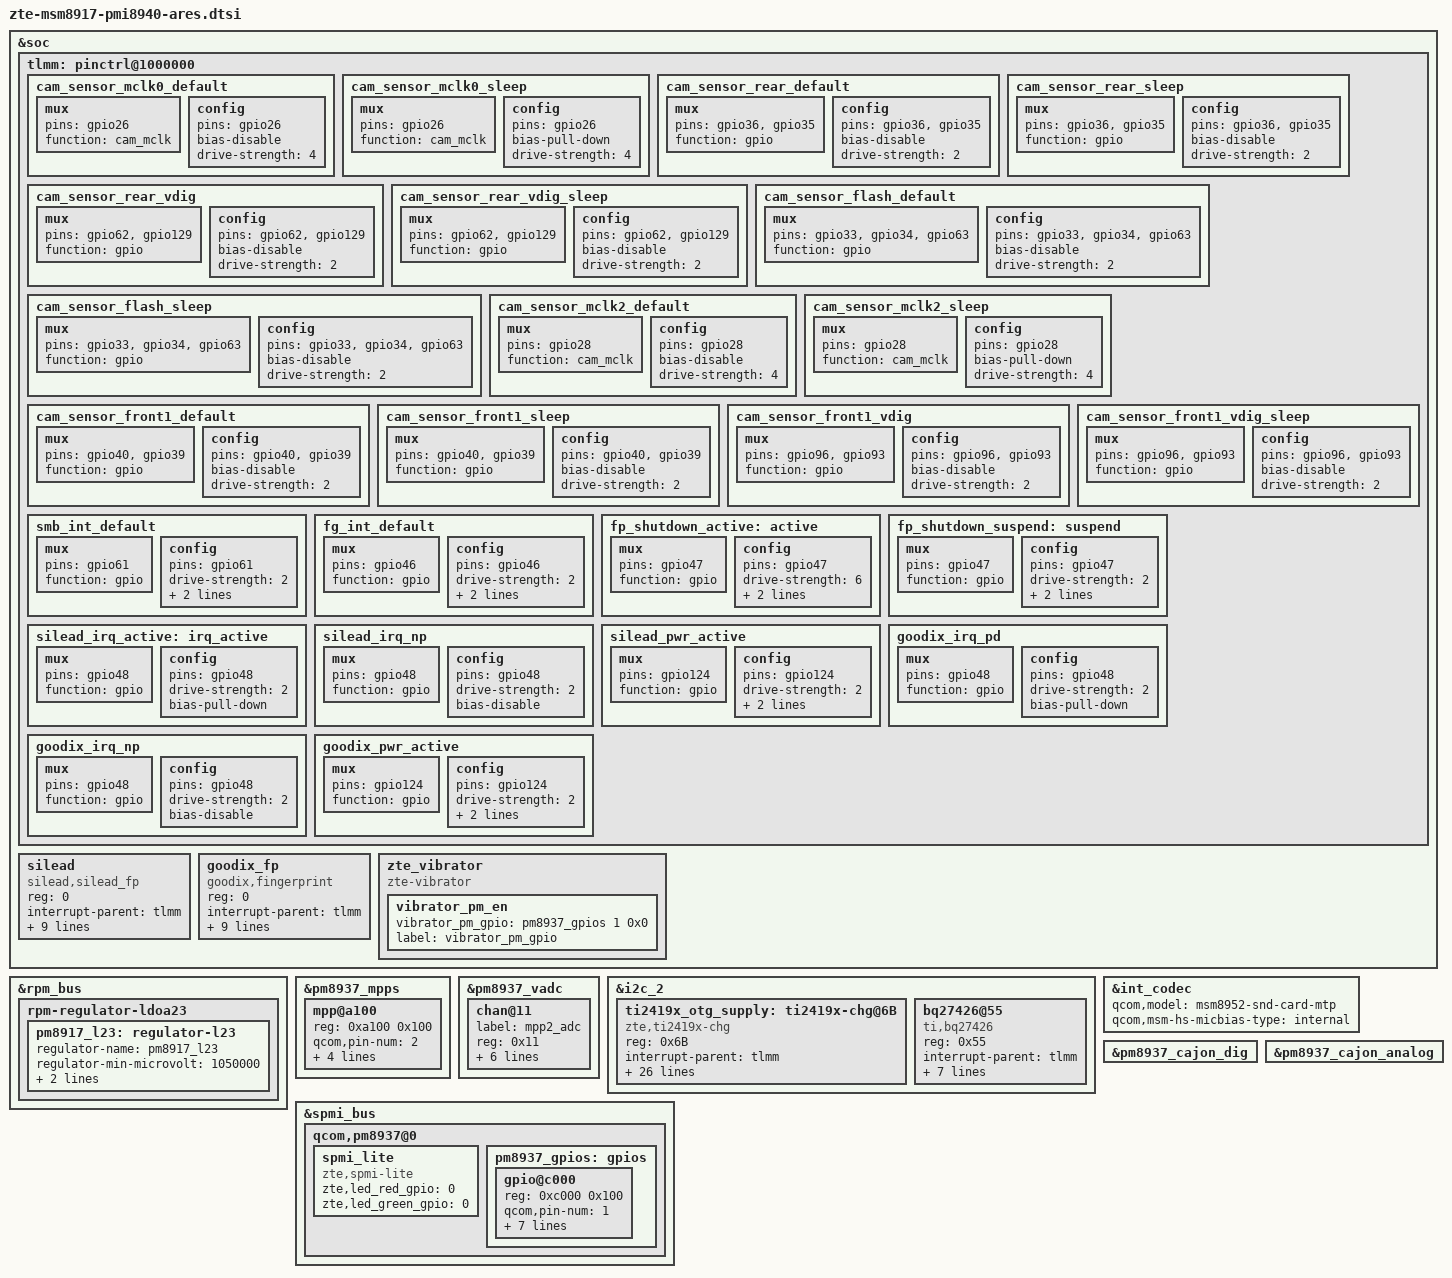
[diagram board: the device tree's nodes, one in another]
/*
 * Copyright (c) 2016, The Linux Foundation. All rights reserved.
 *
 * This program is free software; you can redistribute it and/or modify
 * it under the terms of the GNU General Public License version 2 and
 * only version 2 as published by the Free Software Foundation.
 *
 * This program is distributed in the hope that it will be useful,
 * but WITHOUT ANY WARRANTY; without even the implied warranty of
 * MERCHANTABILITY or FITNESS FOR A PARTICULAR PURPOSE.  See the
 * GNU General Public License for more details.
 */

/*
* device tree for zte ares board
*/

/*ZTE yuxin add for zte Z5151CA ares prj camera gpios 2017.12.16 begin*/
&soc {
	tlmm: pinctrl@1000000 {
	/*sensors */
		cam_sensor_mclk0_default: cam_sensor_mclk0_default {
			/* MCLK0 */
				mux {
				/* CLK, DATA */
				pins = "gpio26";
				function = "cam_mclk";
			};

			config {
				pins = "gpio26";
				bias-disable; /* No PULL */
				drive-strength = <4>; /* 2 MA */
			};
		};

		cam_sensor_mclk0_sleep: cam_sensor_mclk0_sleep {
			/* MCLK0 */
			mux {
				/* CLK, DATA */
				pins = "gpio26";
				function = "cam_mclk";
			};

			config {
				pins = "gpio26";
				bias-pull-down; /* PULL DOWN */
				drive-strength = <4>; /* 2 MA */
			};
		};

		cam_sensor_rear_default: cam_sensor_rear_default {
			/* RESET, STANDBY */
			mux {
				pins = "gpio36", "gpio35";
				function = "gpio";
			};

			config {
				pins = "gpio36","gpio35";
				bias-disable; /* No PULL */
				drive-strength = <2>; /* 2 MA */
			};
		};

		cam_sensor_rear_sleep: cam_sensor_rear_sleep {
			/* RESET, STANDBY */
			mux {
				pins = "gpio36","gpio35";
				function = "gpio";
			};

			config {
				pins = "gpio36","gpio35";
				bias-disable; /* No PULL */
				drive-strength = <2>; /* 2 MA */
			};
		};

		cam_sensor_rear_vdig: cam_sensor_rear_vdig {
			/* VDIG */
			mux {
				pins = "gpio62","gpio129";
				function = "gpio";
			};

			config {
				pins = "gpio62","gpio129";
				bias-disable; /* No PULL */
				drive-strength = <2>; /* 2 MA */
			};
		};

		cam_sensor_rear_vdig_sleep: cam_sensor_rear_vdig_sleep {
			/* VDIG */
			mux {
				pins = "gpio62","gpio129";
				function = "gpio";
			};

			config {
				pins = "gpio62","gpio129";
				bias-disable; /* No PULL */
				drive-strength = <2>; /* 2 MA */
			};
		};
		/*yuxin add for Z5151V flash 20180123 ++*/
		cam_sensor_flash_default: cam_sensor_flash_default {
			/* VDIG */
			mux {
				pins = "gpio33", "gpio34", "gpio63";
				function = "gpio";
			};

			config {
				pins = "gpio33", "gpio34", "gpio63";
				bias-disable; /* No PULL */
				drive-strength = <2>; /* 2 MA */
			};
		};

		cam_sensor_flash_sleep: cam_sensor_flash_sleep {
			/* VDIG */
			mux {
				pins = "gpio33", "gpio34", "gpio63";
				function = "gpio";
			};

			config {
				pins = "gpio33", "gpio34", "gpio63";
				bias-disable; /* No PULL */
				drive-strength = <2>; /* 2 MA */
			};
		};
	/*yuxin add for Z5151V flash 20180123 --*/
		cam_sensor_mclk2_default: cam_sensor_mclk2_default {
			/* MCLK2 */
			mux {
				/* CLK, DATA */
				pins = "gpio28";
				function = "cam_mclk";
			};

			config {
				pins = "gpio28";
				bias-disable; /* No PULL */
				drive-strength = <4>; /* 2 MA */
			};
		};

		cam_sensor_mclk2_sleep: cam_sensor_mclk2_sleep {
			/* MCLK2 */
			mux {
				/* CLK, DATA */
				pins = "gpio28";
				function = "cam_mclk";
			};

			config {
				pins = "gpio28";
				bias-pull-down; /* PULL DOWN */
				drive-strength = <4>; /* 2 MA */
			};
		};

		cam_sensor_front1_default: cam_sensor_front1_default {
			/* RESET, STANDBY */
			mux {
				pins = "gpio40", "gpio39";
				function = "gpio";
			};

			config {
				pins = "gpio40", "gpio39";
				bias-disable; /* No PULL */
				drive-strength = <2>; /* 2 MA */
			};
		};

		cam_sensor_front1_sleep: cam_sensor_front1_sleep {
			/* RESET, STANDBY */
			mux {
				pins = "gpio40", "gpio39";
				function = "gpio";
			};

			config {
				pins = "gpio40", "gpio39";
				bias-disable; /* No PULL */
				drive-strength = <2>; /* 2 MA */
			};
		};
		cam_sensor_front1_vdig: cam_sensor_front1_vdig {
			/* VDIG */
			mux {
				pins = "gpio96", "gpio93";
				function = "gpio";
			};

			config {
				pins = "gpio96", "gpio93";
				bias-disable; /* No PULL */
				drive-strength = <2>; /* 2 MA */
			};
		};

		cam_sensor_front1_vdig_sleep: cam_sensor_front1_vdig_sleep {
			/* VDIG */
			mux {
				pins = "gpio96", "gpio93";
				function = "gpio";
			};

			config {
				pins = "gpio96", "gpio93";
				bias-disable; /* No PULL */
				drive-strength = <2>; /* 2 MA */
			};
		};

		smb_int_default: smb_int_default {
			mux {
				pins = "gpio61";
				function = "gpio";
			};

			config {
				pins = "gpio61";
				drive-strength = <2>;
				bias-disable;
				input-enable;
			};
		};

		fg_int_default: fg_int_default {
			mux {
				pins = "gpio46";
				function = "gpio";
			};

			config {
				pins = "gpio46";
				drive-strength = <2>;
				bias-disable;
				input-enable;
			};
		};
	};
};
/*yuxin modify VREG_L23 voltage range for rear camera DVDD supply 20171222 begin*/
&rpm_bus {
	rpm-regulator-ldoa23 {
		status = "okay";
		pm8917_l23: regulator-l23 {
			regulator-name = "pm8917_l23";
			regulator-min-microvolt = <1050000>;
			regulator-max-microvolt = <1200000>;
			qcom,init-voltage = <1050000>;
			status = "okay";
		};
	};
};
/*yuxin modify VREG_L23 voltage range for rear camera DVDD supply 20171222 end*/

/*ZTE yuxin add for zte Z5151CA ares prj camera gpios 2017.12.16 end*/

&tlmm {
	fp_shutdown_active:active{
		mux{
			pins = "gpio47";
			function = "gpio";
		};
		config{
			pins = "gpio47";
			drive-strength = <6>;
			output-high;
			bias-disable = <0>;
		};
	};

	fp_shutdown_suspend:suspend{
		mux{
			pins = "gpio47";
			function = "gpio";
		};
		config{
			pins = "gpio47";
			drive-strength = <2>;
			output-low;
			bias-disable = <0>;
		};
	};

	silead_irq_active:irq_active{
		mux{
			pins = "gpio48";
			function = "gpio";
		};
		config{
			pins = "gpio48";
			drive-strength = <2>;
			bias-pull-down;
		};
	};
	silead_irq_np:silead_irq_np{
		mux{
			pins = "gpio48";
			function = "gpio";
		};
		config{
			pins = "gpio48";
			drive-strength = <2>;
			bias-disable; /* No PULL */
		};
	};

	silead_pwr_active: silead_pwr_active {
		mux{
			pins = "gpio124";
			function = "gpio";
		};
		config {
			pins = "gpio124";
			drive-strength = <2>;
			bias-disable;
			output-high;
		};
	};

	goodix_irq_pd: goodix_irq_pd{
		mux{
			pins = "gpio48";
			function = "gpio";
		};
		config{
			pins = "gpio48";
			drive-strength = <2>;
			bias-pull-down;
		};
	};
	goodix_irq_np: goodix_irq_np{
		mux{
			pins = "gpio48";
			function = "gpio";
		};
		config{
			pins = "gpio48";
			drive-strength = <2>;
			bias-disable; /* No PULL */
		};
	};
	goodix_pwr_active: goodix_pwr_active {
		mux{
			pins = "gpio124";
			function = "gpio";
		};
		config {
			pins = "gpio124";
			drive-strength = <2>;
			bias-disable;
			output-high;
		};
	};
};
&soc {
	/* zte for fingerprint */
	silead {
		status = "ok";
		reg = <0>;
		compatible = "silead,silead_fp";
		interrupt-parent = <&tlmm>;
		interrupts = <97 0x0>;

		pinctrl-names = "silead_active", "silead_suspend", "silead_irq", "pwr_active", "silead_irq_np";
		pinctrl-0 = <&fp_shutdown_active>;
		pinctrl-1 = <&fp_shutdown_suspend>;
		pinctrl-2 = <&silead_irq_active>;
		pinctrl-3 = <&silead_pwr_active>;
		pinctrl-4 = <&silead_irq_np>;

		silead,gpio_reset = <&tlmm 47 0>;
		silead,gpio_irq = <&tlmm 48 0>;
		silead,gpio_pwr = <&tlmm 124 0>;
		interrupt-names = "sl_wake_up";
	};

	goodix_fp {
		status = "ok";
		reg = <0>;
		compatible = "goodix,fingerprint";
		interrupt-parent = <&tlmm>;
		interrupts = <48 0x0>;

		pinctrl-names = "goodix_active", "goodix_suspend", "goodix_irq_pd", "goodix_irq_np", "pwr_active";
		pinctrl-0 = <&fp_shutdown_active>;
		pinctrl-1 = <&fp_shutdown_suspend>;
		pinctrl-2 = <&goodix_irq_pd>;
		pinctrl-3 = <&goodix_irq_np>;
		pinctrl-4 = <&goodix_pwr_active>;

		fp-gpio-reset = <&tlmm 47 0>;
		fp-gpio-irq = <&tlmm 48 0>;
		goodix,gpio_pwr = <&tlmm 124 0>;
		interrupt-names = "goodix_wake_up";
	};

	zte_vibrator {
		compatible = "zte-vibrator";
		vibrator_pm_en{
			vibrator_pm_gpio = <&pm8937_gpios 1 0x0>;
			label = "vibrator_pm_gpio";
		};
	};
};

&pm8937_mpps {
		mpp@a100 {
		/* MPP2 - BATT_ID config */
		reg = <0xa100 0x100>;
		qcom,pin-num = <2>;
		qcom,mode = <4>; /* AIN input */
		qcom,ain-route = <1>; /* AMUX 6 */
		qcom,master-en = <1>;
		qcom,src-sel = <0>; /* Function constant */
		/delete-property/qcom,invert;
		};
};

&pm8937_vadc {
		chan@11 {
		label = "mpp2_adc";
		reg = <0x11>;
		qcom,decimation = <0>;
		qcom,pre-div-channel-scaling = <0>;
		qcom,calibration-type = "absolute";
		qcom,scale-function = <0>;
		qcom,hw-settle-time = <1>;
		qcom,fast-avg-setup = <2>;
		/delete-property/qcom,vadc-thermal-node;
	};
};

&i2c_2 {
	ti2419x_otg_supply: ti2419x-chg@6B {
		compatible = "zte,ti2419x-chg";
		reg = <0x6B>;
		interrupt-parent = <&tlmm>;
		interrupts = <61 2>;
		pinctrl-names = "default";
		pinctrl-0 = <&smb_int_default>;
		regulator-name = "ti2419x_otg_vreg";

		zte,float-voltage-mv = <4400>;
		zte,iterm-ma = <150>;
		/*zte,hw-iterm-disabled;*/
		/*zte,charging-disabled; changed by zte */
		zte,recharge-thresh-mv = <100>;
		zte,warm_recharge-thresh-mv = <50>;
		zte,vbatdet-max-err-mv = <20>;
		zte,charging-timeout = <10>;
		zte,input_voltage_mv = <4520>;
		zte,max_usb_current = <2100>;
		zte,max_battery_current = <3000>;
		zte,thermal-mitigation = <1500 1000 700 500 0>;
		zte,warm_bat_mv = <4100>;
		zte,cool_bat_mv = <4400>;
		zte,warm-bat-decidegc = <440>;
		zte,cool-bat-decidegc = <100>;
		zte,cooler-bat-decidegc = <50>;
		zte,hot-bat-decidegc = <500>;
		zte,cold-bat-decidegc = <10>;
		zte,warm_bat_chg_ma = <700>;
		zte,cool_bat_chg_ma = <700>;
		zte,cooler_bat_chg_ma = <300>;	 /* 0~5 */
		qcom,tichg-vadc = <&pm8937_vadc>;
		zte,batt-hot-percentage = <20>; /*Only for k81:-5~49*/
		zte,batt-cold-percentage= <75>; /*Only for k81:-5~49*/
	};

	bq27426@55 {
		compatible = "ti,bq27426";
		reg = <0x55>;
		interrupt-parent = <&tlmm>;
		interrupts = <46 2>;
		pinctrl-names = "default";
		pinctrl-0 = <&fg_int_default>;
		qcom,irq-gpio = <&tlmm 46 0x0>;
		qcom,batt_id-vadc = <&pm8937_vadc>;
		qcom,batt-id-vref-uv = <1800000>;
		qcom,batt-id-rpullup-kohm = <10>;
		qcom,batt_full_design_capacity = <3100>;
	};
};

&spmi_bus {
	qcom,pm8937@0 {
		spmi_lite {
			compatible = "zte,spmi-lite";
			zte,led_red_gpio = <0>;
			zte,led_green_gpio = <0>;
		};

		pm8937_gpios: gpios {
			gpio@c000 {
				reg = <0xc000 0x100>;
				qcom,pin-num = <1>;
				qcom,mode = <0>;
				qcom,output-type = <0>;
				qcom,pull = <0>;
				qcom,vin-sel = <3>;
				qcom,out-strength = <3>;
				qcom,src-sel = <0>;
				qcom,master-en = <0>;
				//qcom,dtest-sel = <1>;
				status = "okay";
			};
		};
	};
};

&int_codec {
	status = "okay";
	qcom,model = "msm8952-snd-card-mtp";
	qcom,msm-hs-micbias-type = "internal";
};

&pm8937_cajon_dig {
	status = "okay";
};

&pm8937_cajon_analog {
	status = "okay";
};
